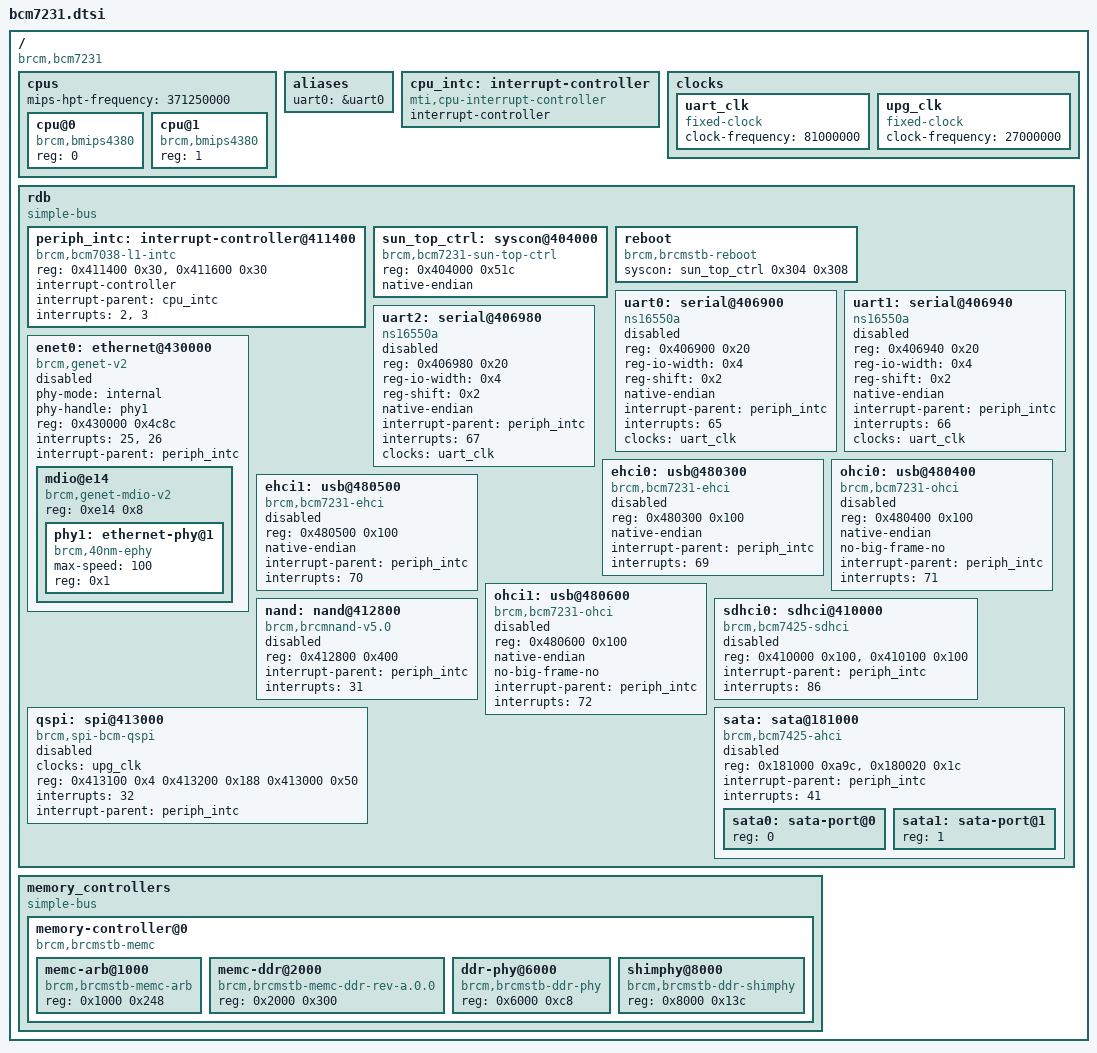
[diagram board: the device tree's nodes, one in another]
// SPDX-License-Identifier: GPL-2.0
/* Broadcom BCM7231 (dual-core BMIPS4380) set-top box SoC.
 * Register map and IRQs derived from SmartLabs SML-482 HD Base
 * vendor kernel 3.3.8 (sml723x) /proc/iomem + /proc/interrupts.
 */
/ {
	#address-cells = <1>;
	#size-cells = <1>;
	compatible = "brcm,bcm7231";

	cpus {
		#address-cells = <1>;
		#size-cells = <0>;

		mips-hpt-frequency = <371250000>;

		cpu@0 {
			compatible = "brcm,bmips4380";
			device_type = "cpu";
			reg = <0>;
		};

		cpu@1 {
			compatible = "brcm,bmips4380";
			device_type = "cpu";
			reg = <1>;
		};
	};

	aliases {
		uart0 = &uart0;
	};

	cpu_intc: interrupt-controller {
		#address-cells = <0>;
		compatible = "mti,cpu-interrupt-controller";

		interrupt-controller;
		#interrupt-cells = <1>;
	};

	clocks {
		uart_clk: uart_clk {
			compatible = "fixed-clock";
			#clock-cells = <0>;
			clock-frequency = <81000000>;
		};

		upg_clk: upg_clk {
			compatible = "fixed-clock";
			#clock-cells = <0>;
			clock-frequency = <27000000>;
		};
	};

	rdb {
		#address-cells = <1>;
		#size-cells = <1>;

		compatible = "simple-bus";
		ranges = <0 0x10000000 0x01000000>;

		periph_intc: interrupt-controller@411400 {
			compatible = "brcm,bcm7038-l1-intc";
			reg = <0x411400 0x30>, <0x411600 0x30>;

			interrupt-controller;
			#interrupt-cells = <1>;

			interrupt-parent = <&cpu_intc>;
			interrupts = <2>, <3>;
		};

		sun_top_ctrl: syscon@404000 {
			compatible = "brcm,bcm7231-sun-top-ctrl", "syscon";
			reg = <0x404000 0x51c>;
			native-endian;
		};

		reboot {
			compatible = "brcm,brcmstb-reboot";
			syscon = <&sun_top_ctrl 0x304 0x308>;
		};

		uart0: serial@406900 {
			compatible = "ns16550a";
			reg = <0x406900 0x20>;
			reg-io-width = <0x4>;
			reg-shift = <0x2>;
			native-endian;
			interrupt-parent = <&periph_intc>;
			interrupts = <65>;
			clocks = <&uart_clk>;
			status = "disabled";
		};

		uart1: serial@406940 {
			compatible = "ns16550a";
			reg = <0x406940 0x20>;
			reg-io-width = <0x4>;
			reg-shift = <0x2>;
			native-endian;
			interrupt-parent = <&periph_intc>;
			interrupts = <66>;
			clocks = <&uart_clk>;
			status = "disabled";
		};

		uart2: serial@406980 {
			compatible = "ns16550a";
			reg = <0x406980 0x20>;
			reg-io-width = <0x4>;
			reg-shift = <0x2>;
			native-endian;
			interrupt-parent = <&periph_intc>;
			interrupts = <67>;
			clocks = <&uart_clk>;
			status = "disabled";
		};

		enet0: ethernet@430000 {
			phy-mode = "internal";
			phy-handle = <&phy1>;
			compatible = "brcm,genet-v2";
			#address-cells = <0x1>;
			#size-cells = <0x1>;
			reg = <0x430000 0x4c8c>;
			interrupts = <25>, <26>;
			interrupt-parent = <&periph_intc>;
			status = "disabled";

			mdio@e14 {
				compatible = "brcm,genet-mdio-v2";
				#address-cells = <0x1>;
				#size-cells = <0x0>;
				reg = <0xe14 0x8>;

				phy1: ethernet-phy@1 {
					max-speed = <100>;
					reg = <0x1>;
					compatible = "brcm,40nm-ephy",
						     "ethernet-phy-ieee802.3-c22";
				};
			};
		};

		ehci0: usb@480300 {
			compatible = "brcm,bcm7231-ehci", "generic-ehci";
			reg = <0x480300 0x100>;
			native-endian;
			interrupt-parent = <&periph_intc>;
			interrupts = <69>;
			status = "disabled";
		};

		ohci0: usb@480400 {
			compatible = "brcm,bcm7231-ohci", "generic-ohci";
			reg = <0x480400 0x100>;
			native-endian;
			no-big-frame-no;
			interrupt-parent = <&periph_intc>;
			interrupts = <71>;
			status = "disabled";
		};

		ehci1: usb@480500 {
			compatible = "brcm,bcm7231-ehci", "generic-ehci";
			reg = <0x480500 0x100>;
			native-endian;
			interrupt-parent = <&periph_intc>;
			interrupts = <70>;
			status = "disabled";
		};

		ohci1: usb@480600 {
			compatible = "brcm,bcm7231-ohci", "generic-ohci";
			reg = <0x480600 0x100>;
			native-endian;
			no-big-frame-no;
			interrupt-parent = <&periph_intc>;
			interrupts = <72>;
			status = "disabled";
		};

		sdhci0: sdhci@410000 {
			compatible = "brcm,bcm7425-sdhci";
			reg = <0x410000 0x100>, <0x410100 0x100>;
			reg-names = "host", "cfg";
			interrupt-parent = <&periph_intc>;
			interrupts = <86>;
			status = "disabled";
		};

		nand: nand@412800 {
			compatible = "brcm,brcmnand-v5.0", "brcm,brcmnand";
			#address-cells = <1>;
			#size-cells = <0>;
			reg-names = "nand";
			reg = <0x412800 0x400>;
			interrupt-parent = <&periph_intc>;
			interrupts = <31>;
			status = "disabled";
		};

		qspi: spi@413000 {
			#address-cells = <0x1>;
			#size-cells = <0x0>;
			compatible = "brcm,spi-bcm-qspi",
				     "brcm,spi-brcmstb-qspi";
			clocks = <&upg_clk>;
			reg = <0x413100 0x4 0x413200 0x188 0x413000 0x50>;
			reg-names = "cs_reg", "hif_mspi", "bspi";
			interrupts = <32>;
			interrupt-parent = <&periph_intc>;
			interrupt-names = "mspi_done";
			status = "disabled";
		};

		sata: sata@181000 {
			compatible = "brcm,bcm7425-ahci", "brcm,sata3-ahci";
			reg-names = "ahci", "top-ctrl";
			reg = <0x181000 0xa9c>, <0x180020 0x1c>;
			interrupt-parent = <&periph_intc>;
			interrupts = <41>;
			#address-cells = <1>;
			#size-cells = <0>;
			status = "disabled";

			sata0: sata-port@0 {
				reg = <0>;
			};

			sata1: sata-port@1 {
				reg = <1>;
			};
		};
	};

	memory_controllers {
		compatible = "simple-bus";
		ranges = <0x0 0x103b0000 0xa000>;
		#address-cells = <1>;
		#size-cells = <1>;

		memory-controller@0 {
			compatible = "brcm,brcmstb-memc", "simple-bus";
			ranges = <0x0 0x0 0xa000>;
			#address-cells = <1>;
			#size-cells = <1>;

			memc-arb@1000 {
				compatible = "brcm,brcmstb-memc-arb";
				reg = <0x1000 0x248>;
			};

			memc-ddr@2000 {
				compatible = "brcm,brcmstb-memc-ddr-rev-a.0.0",
					     "brcm,brcmstb-memc-ddr";
				reg = <0x2000 0x300>;
			};

			ddr-phy@6000 {
				compatible = "brcm,brcmstb-ddr-phy";
				reg = <0x6000 0xc8>;
			};

			shimphy@8000 {
				compatible = "brcm,brcmstb-ddr-shimphy";
				reg = <0x8000 0x13c>;
			};
		};
	};
};
